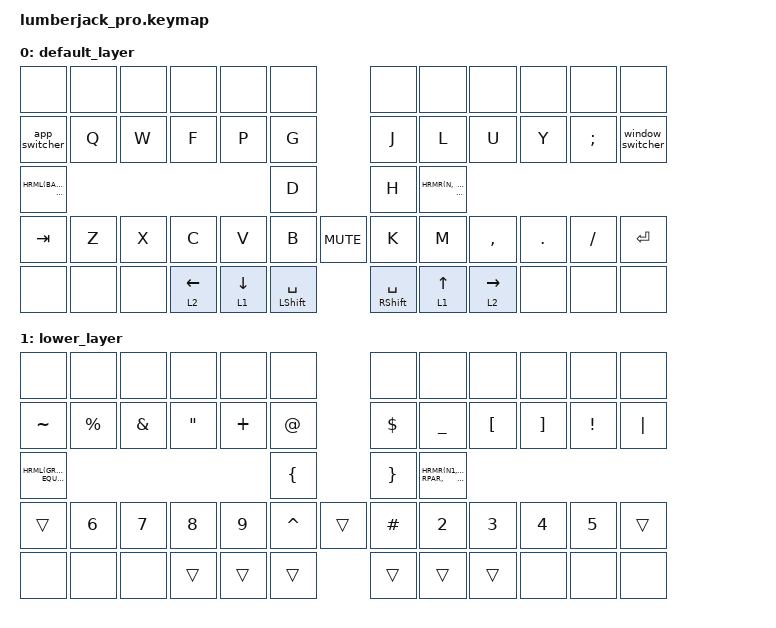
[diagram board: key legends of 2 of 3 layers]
/*
 * Copyright (c) 2021 The ZMK Contributors
 *
 * SPDX-License-Identifier: MIT
 */

#include <behaviors.dtsi>
#include <dt-bindings/zmk/bt.h>
#include <dt-bindings/zmk/keys.h>

#define BASE 0
#define LOWER 1
#define RAISE 2
#define LMEH LS(LC(LALT))
#define RMEH RS(RC(RALT))
#define LHYPER LG(LMEH)
#define RHYPER RG(RMEH)
#define HRML(k1,k2,k3,k4,k5) &hml LMEH k1  &hml LHYPER k2  &hml LCTRL k3  &hml LALT k4  &hml LGUI k5
#define HRMR(k1,k2,k3,k4,k5) &hmr RGUI k1  &hmr RALT k2  &hmr RCTRL k3  &hmr RHYPER k4  &hmr RMEH k5

/* Uncomment to enable the encoder */
&sensors { status = "okay"; };
&encoder { status = "okay"; };

/ {
    macros {
        app_switcher: app_switcher {
            compatible = "zmk,behavior-macro";
            #binding-cells = <0>;
            bindings =
                <&macro_press>,
                <&kp LCMD>,
                <&macro_tap>,
                <&kp TAB>,
                <&macro_tap>,
                <&sk LCMD>,
                <&macro_release>,
                <&kp LCMD>;

            tap-ms = <10>;
            wait-ms = <50>;
        };

        window_switcher: window_switcher {
            compatible = "zmk,behavior-macro";
            #binding-cells = <0>;
            bindings =
                <&macro_press>,
                <&kp LALT>,
                <&macro_tap>,
                <&kp TAB>,
                <&macro_tap>,
                <&sk LALT>,
                <&macro_release>,
                <&kp LALT>;

            tap-ms = <10>;
            wait-ms = <50>;
        };
    };

    behaviors {
        hmsl: hm_shft_left {
            compatible = "zmk,behavior-hold-tap";
            bindings = <&kp>, <&kp>;
            #binding-cells = <2>;
            tapping-term-ms = <200>;
            hold-while-undecided;
            hold-trigger-on-release;
            flavor = "tap-preferred";
        };

        hmsr: hm_shft_right {
            compatible = "zmk,behavior-hold-tap";
            bindings = <&kp>, <&kp>;
            #binding-cells = <2>;
            tapping-term-ms = <200>;
            hold-while-undecided;
            hold-trigger-on-release;
            flavor = "tap-preferred";
        };

        hml: hm_left {
            compatible = "zmk,behavior-hold-tap";
            bindings = <&kp>, <&kp>;
            #binding-cells = <2>;
            tapping-term-ms = <200>;
            hold-while-undecided;
            hold-trigger-key-positions = <18 19 20 21 22 30 31 32 33 34 43 44 45 46 47>;
            hold-trigger-on-release;
            flavor = "tap-preferred";
        };

        hmr: hm_right {
            compatible = "zmk,behavior-hold-tap";
            bindings = <&kp>, <&kp>;
            #binding-cells = <2>;
            tapping-term-ms = <200>;
            hold-while-undecided;
            hold-trigger-key-positions = <13 14 15 16 17 25 26 27 28 29 37 38 39 40 41>;
            hold-trigger-on-release;
            flavor = "tap-preferred";
        };
    };

    keymap {
        compatible = "zmk,keymap";

        default_layer {
            bindings = <
&none            &none            &none               &none           &none              &none                             &none                  &none                &none            &none                &none          &none
&app_switcher    &kp Q            &kp W               &kp F           &kp P              &kp G                             &kp J                  &kp L                &kp U            &kp Y                &kp SEMICOLON  &window_switcher
HRML(BACKSPACE,  A,               R,                  S,              T)                 &kp D                             &kp H                  HRMR(N,              E,               I,                   O,             ESCAPE)
&kp TAB          &kp Z            &kp X               &kp C           &kp V              &kp B                 &kp C_MUTE  &kp K                  &kp M                &kp COMMA        &kp DOT              &kp FSLH       &kp RET
&none            &none            &none               &lt 2 LEFT      &lt 1 DOWN         &hmsl LSHFT SPACE                 &hmsr RSHFT SPACE      &lt 1 UP             &lt 2 RIGHT      &none                &none          &none
            >;

            sensor-bindings = <&inc_dec_kp C_VOL_UP C_VOL_DN>;
        };

        lower_layer {
            bindings = <
&none        &none            &none           &none               &none              &none                   &none             &none                &none                   &none                &none            &none
&kp TILDE    &kp PERCENT      &kp AMPERSAND   &kp DOUBLE_QUOTES   &kp PLUS           &kp AT_SIGN             &kp DOLLAR        &kp UNDERSCORE       &kp LEFT_BRACKET        &kp RIGHT_BRACKET    &kp EXCLAMATION  &kp PIPE
HRML(GRAVE,  SQT,             LPAR,           EQUAL,              N0)                &kp LEFT_BRACE          &kp RIGHT_BRACE   HRMR(N1,             STAR,                   RPAR,                MINUS,           BACKSLASH)
&trans       &kp N6           &kp N7          &kp N8              &kp N9             &kp CARET       &trans  &kp HASH          &kp N2               &kp N3                  &kp N4               &kp N5           &trans
&none        &none            &none          &trans               &trans             &trans                  &trans            &trans               &trans                  &none                &none            &none
            >;

            sensor-bindings = <&inc_dec_kp PG_UP PG_DN>;
        };

        raise_layer {
            bindings = <
&none            &none           &none          &none          &none       &none                       &none            &none                    &none        &none       &none               &none
&bt BT_SEL 0     &bt BT_SEL 1    &bt BT_DISC 0  &bt BT_DISC 1  &bt BT_CLR  &bt BT_CLR_ALL              &kp C_PREV       &kp C_PP                 &kp C_NEXT   &none       &none               &none
&none  		 &kp F12         &kp LCTRL      &kp LALT       &kp LCMD    &none                       &kp LEFT         HRMR(DOWN,               UP,          RIGHT,      F11,                ESCAPE)
&trans           &kp F6          &kp F7         &kp F8         &kp F9      &kp F10         &trans      &kp F1           &kp F2                   &kp F3       &kp F4      &kp F5              &trans
&none            &none           &none          &trans         &trans      &kp LSHFT                   &kp RSHFT        &trans                   &trans       &none       &none               &none
            >;

        };
    };
};
